# H6 register map
Vendor: Allwinner; Series: H6; File version: 0.1
CPU: CA53 0, little endian, MPU, no FPU, 0 interrupt priority bits
Registers are 32-bit, read-write, reset 0x0 unless marked. A register's access mark holds for its fields unless they carry their own. Offsets are from the block's base; [hi:lo] are bit positions; {n}, {i} and the like mark numbered series; 'fields as' and 'values as' point back to an identical list.

## CCU
Base 0x03001000
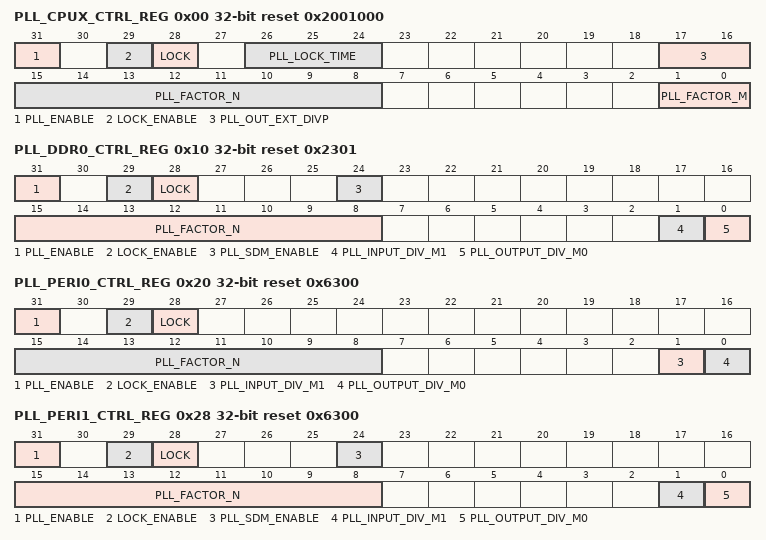
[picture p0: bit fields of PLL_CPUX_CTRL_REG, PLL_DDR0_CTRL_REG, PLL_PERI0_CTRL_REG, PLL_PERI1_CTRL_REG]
0x00 PLL_CPUX_CTRL_REG reset 0x2001000 — PLL_CPUX Control Register
  [31] PLL_ENABLE — 0: Disable. 1: Enable. The PLL_CPUX= 24MHz*N/P. NOTE The PLL_CPUX output clock must be in the range of 200MHz~3GHz. Its default value is 408MHz.
    0=Disable; 1=Enable. The PLL_CPUX= 24MHz*N/P. NOTE The PLL_CPUX output clock must be in the range of 200MHz~3GHz. Its default value is 408MHz.
  [29] LOCK_ENABLE — Lock Enable 0: Disable 1: Enable
    0=Disable; 1=Enable
  [28] LOCK ro — 0:Unlocked 1: Locked (It indicates that the PLL has been stable.)
    1=Locked (It indicates that the PLL has been stable.)
  [26:24] PLL_LOCK_TIME — PLL Lock Time. This bit is a stepping range from a frequency to another frequency,it can adjust the speed of clock changing.
  [17:16] PLL_OUT_EXT_DIVP — PLL Output External Divider P. 00: 1 01: 2 10: 4 11: / When output clock is less than 288MHz,clock frequency is outputted by dividing P.
    0=_1; 1=_2; 2=_4; 3=_slash_ (/ When output clock is less than 288MHz,clock frequency is outputted by dividing P.)
  [15:8] PLL_FACTOR_N — PLL Factor N. N= PLL_FACTOR_N +1 PLL_FACTOR_N is from 0 to 254. In application, PLL_FACTOR_N should be more than or equal to 11
  [1:0] PLL_FACTOR_M — PLL Factor M M = PLL_FACTOR_M + 1 PLL_FACTOR_M is from 0 to 3. M is only used for backdoor testing.
0x10 PLL_DDR0_CTRL_REG reset 0x2301 — PLL_DDR0 Control Register
  [31] PLL_ENABLE — 0: Disable. 1: Enable. The PLL_DDR0 = 24MHz*N/M0/M1. PLL_DDR0 is 432MHz by default.
    0=Disable; 1=Enable. The PLL_DDR0 = 24MHz*N/M0/M1. PLL_DDR0 is 432MHz by default.
  [29] LOCK_ENABLE — Lock Enable 0: Disable 1: Enable
    0=Disable; 1=Enable
  [28] LOCK ro — 0:Unlocked 1: Locked (It indicates that the PLL has been stable.)
    1=Locked (It indicates that the PLL has been stable.)
  [24] PLL_SDM_ENABLE — 0: Disable. 1: Enable.
    0=Disable; 1=Enable
  [15:8] PLL_FACTOR_N — PLL Factor N. N= PLL_FACTOR_N +1 PLL_FACTOR_N is from 0 to 254. In application, PLL_FACTOR_N should be more than or equal to 11.
  [1] PLL_INPUT_DIV_M1 — PLL Input Div M1. M1=PLL_INPUT_DIV_M1 + 1 PLL_INPUT_DIV_M1 is from 0 to 1.
  [0] PLL_OUTPUT_DIV_M0 — PLL Output Div M0. M0=PLL_OUTPUT_DIV_M0 + 1 PLL_OUTPUT_DIV_M0 is from 0 to 1.
0x20 PLL_PERI0_CTRL_REG reset 0x6300 — PLL_PERI0 Control Register
  [31] PLL_ENABLE — 0: Disable. 1: Enable. The PLL_PERI0(4X) = 24MHz*N/M0/M1. The PLL_PERI0(2X) = (24MHz*N/M0/M1)/2. The PLL_PERI0(1X) = (24MHz*N/M0/M1)/4. PLL_PERI0(4X) is 2.4GHz by default. PLL_PERI0(4X) output clock should be 2.4GHz. It is not suggested to change this parameter.
    0=Disable; 1=Enable. The PLL_PERI0(4X) = 24MHz*N/M0/M1. The PLL_PERI0(2X) = (24MHz*N/M0/M1)/2. The PLL_PERI0(1X) = (24MHz*N/M0/M1)/4. PLL_PERI0(4X) is 2.4GHz by default. PLL_PERI0(4X) output clock should be 2.4GHz. It is not suggested to change this parameter.
  [29] LOCK_ENABLE — Lock Enable 0: Disable 1: Enable
    0=Disable; 1=Enable
  [28] LOCK ro — 0:Unlocked 1: Locked (It indicates that the PLL has been stable.)
    1=Locked (It indicates that the PLL has been stable.)
  [15:8] PLL_FACTOR_N — PLL Factor N. N= PLL_FACTOR_N +1 PLL_FACTOR_N is from 0 to 254. In application, PLL_FACTOR_N should be more than or equal to 11
  [1] PLL_INPUT_DIV_M1 — PLL Input Div M1. M1=PLL_INPUT_DIV_M1 + 1 PLL_INPUT_DIV_M1 is from 0 to 1.
  [0] PLL_OUTPUT_DIV_M0 — PLL Output Div M0. M0=PLL_OUTPUT_DIV_M0 + 1 PLL_OUTPUT_DIV_M0 is from 0 to 1.
0x28 PLL_PERI1_CTRL_REG reset 0x6300 — PLL_PERI1 Control Register
  [31] PLL_ENABLE — 0: Disable. 1: Enable. The PLL_PERI1(4X) = 24MHz*N/M0/M1. The PLL_PERI1(2X) = (24MHz*N/M0/M1)/2. The PLL_PERI1(1X) = (24MHz*N/M0/M1)/4. PLL_PERI1(4X) is 2.4GHz by default. PLL_PERI1(4X) output clock should be 2.4GHz. It is not suggested to change this parameter.
    0=Disable; 1=Enable. The PLL_PERI1(4X) = 24MHz*N/M0/M1. The PLL_PERI1(2X) = (24MHz*N/M0/M1)/2. The PLL_PERI1(1X) = (24MHz*N/M0/M1)/4. PLL_PERI1(4X) is 2.4GHz by default. PLL_PERI1(4X) output clock should be 2.4GHz. It is not suggested to change this parameter.
  [29] LOCK_ENABLE — Lock Enable 0: Disable 1: Enable
    0=Disable; 1=Enable
  [28] LOCK ro — 0:Unlocked 1: Locked (It indicates that the PLL has been stable.)
    1=Locked (It indicates that the PLL has been stable.)
  [24] PLL_SDM_ENABLE — 0: Disable. 1: Enable.
    0=Disable; 1=Enable
  [15:8] PLL_FACTOR_N — PLL Factor N. N= PLL_FACTOR_N +1 PLL_FACTOR_N is from 0 to 254. In application, PLL_FACTOR_N should be more than or equal to 11.
  [1] PLL_INPUT_DIV_M1 — PLL Input Div M1. M1=PLL_INPUT_DIV_M1 + 1 PLL_INPUT_DIV_M1 is from 0 to 1.
  [0] PLL_OUTPUT_DIV_M0 — PLL Output Div M0. M0=PLL_OUTPUT_DIV_M0 + 1 PLL_OUTPUT_DIV_M0 is from 0 to 1.
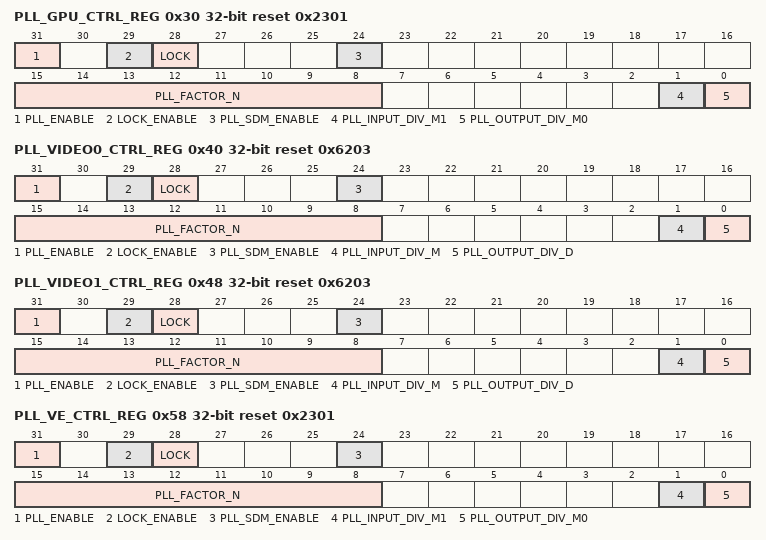
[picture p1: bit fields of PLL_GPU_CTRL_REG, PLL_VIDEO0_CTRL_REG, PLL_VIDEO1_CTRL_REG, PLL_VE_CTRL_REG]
0x30 PLL_GPU_CTRL_REG reset 0x2301 — PLL_GPU Control Register
  [31] PLL_ENABLE — 0: Disable. 1: Enable. The PLL_GPU = 24MHz*N/M0/M1. PLL_GPU is 432MHz by default.
    0=Disable; 1=Enable. The PLL_GPU = 24MHz*N/M0/M1. PLL_GPU is 432MHz by default.
  [29] LOCK_ENABLE — Lock Enable 0: Disable 1: Enable
    0=Disable; 1=Enable
  [28] LOCK ro — 0:Unlocked 1: Locked (It indicates that the PLL has been stable.)
    1=Locked (It indicates that the PLL has been stable.)
  [24] PLL_SDM_ENABLE — 0: Disable. 1: Enable.
    0=Disable; 1=Enable
  [15:8] PLL_FACTOR_N — PLL Factor N. N= PLL_FACTOR_N +1 PLL_FACTOR_N is from 0 to 254. In application, PLL_FACTOR_N should be more than or equal to 11.
  [1] PLL_INPUT_DIV_M1 — PLL Input Div M1. M1=PLL_INPUT_DIV_M1 + 1 PLL_INPUT_DIV_M1 is from 0 to 1.
  [0] PLL_OUTPUT_DIV_M0 — PLL Output Div M0. M0=PLL_OUTPUT_DIV_M0 + 1 PLL_OUTPUT_DIV_M0 is from 0 to 1.
0x40 PLL_VIDEO0_CTRL_REG reset 0x6203 — PLL_VIDEO0 Control Register
  [31] PLL_ENABLE — 0: Disable. 1: Enable. For application, PLL_VIDEO0(4X)= 24MHz*N/M. PLL_VIDEO0(1X)=24MHz*N/M/4. PLL_VIDEO0 is 1188MHz by default.
    0=Disable; 1=Enable. For application, PLL_VIDEO0(4X)= 24MHz*N/M. PLL_VIDEO0(1X)=24MHz*N/M/4. PLL_VIDEO0 is 1188MHz by default.
  [29] LOCK_ENABLE — Lock Enable 0: Disable 1: Enable
    0=Disable; 1=Enable
  [28] LOCK ro — 0:Unlocked 1: Locked (It indicates that the PLL has been stable.)
    1=Locked (It indicates that the PLL has been stable.)
  [24] PLL_SDM_ENABLE — 0: Disable. 1: Enable.
    0=Disable; 1=Enable
  [15:8] PLL_FACTOR_N — PLL Factor N. N= PLL_FACTOR_N +1 PLL_FACTOR_N is from 0 to 254. In application, PLL_FACTOR_N should be more than or equal to 11
  [1] PLL_INPUT_DIV_M — PLL Input Div M. M1=PLL_INPUT_DIV_M + 1 PLL_INPUT_DIV_M is from 0 to 1.
  [0] PLL_OUTPUT_DIV_D — PLL Output Div D. ( This factor is used for testing.) M0=PLL_OUTPUT_DIV_D + 1 PLL_OUTPUT_DIV_D is from 0 to 1. For test, PLL_VIDEO0(4X) =24MHz*N/M/D
0x48 PLL_VIDEO1_CTRL_REG reset 0x6203 — PLL_VIDEO1 Control Register
  [31] PLL_ENABLE — 0: Disable. 1: Enable. For application, PLL_VIDEO1(4X)= 24MHz*N/M. PLL_VIDEO1(1X)=24MHz*N/M/4. PLL_VIDEO0 is 1188MHz by default.
    0=Disable; 1=Enable. For application, PLL_VIDEO1(4X)= 24MHz*N/M. PLL_VIDEO1(1X)=24MHz*N/M/4. PLL_VIDEO0 is 1188MHz by default.
  [29] LOCK_ENABLE — Lock Enable 0: Disable 1: Enable
    0=Disable; 1=Enable
  [28] LOCK ro — 0:Unlocked 1: Locked (It indicates that the PLL has been stable.)
    1=Locked (It indicates that the PLL has been stable.)
  [24] PLL_SDM_ENABLE — 0: Disable. 1: Enable.
    0=Disable; 1=Enable
  [15:8] PLL_FACTOR_N — PLL Factor N. N= PLL_FACTOR_N +1 PLL_FACTOR_N is from 0 to 254. In application, PLL_FACTOR_N should be more than or equal to 11
  [1] PLL_INPUT_DIV_M — PLL Input Div M. M1=PLL_INPUT_DIV_M + 1 PLL_INPUT_DIV_M is from 0 to 1.
  [0] PLL_OUTPUT_DIV_D — PLL Output Div D.( This factor is used for testing.) M0=PLL_OUTPUT_DIV_D + 1 PLL_OUTPUT_DIV_M0 is from 0 to 1. For test, PLL_VIDEO1(4X) =24MHz*N/M/D
0x58 PLL_VE_CTRL_REG reset 0x2301 — PLL_VE Control Register
  [31] PLL_ENABLE — 0: Disable. 1: Enable. The PLL_VE = 24MHz*N/M0/M1. PLL_VE is 432MHz by default.
    0=Disable; 1=Enable. The PLL_VE = 24MHz*N/M0/M1. PLL_VE is 432MHz by default.
  [29] LOCK_ENABLE — Lock Enable 0: Disable 1: Enable
    0=Disable; 1=Enable
  [28] LOCK ro — 0:Unlocked 1: Locked (It indicates that the PLL has been stable.)
    1=Locked (It indicates that the PLL has been stable.)
  [24] PLL_SDM_ENABLE — 0: Disable. 1: Enable.
    0=Disable; 1=Enable
  [15:8] PLL_FACTOR_N — PLL Factor N. N= PLL_FACTOR_N +1 PLL_FACTOR_N is from 0 to 254. In application, PLL_FACTOR_N should be more than or equal to 11
  [1] PLL_INPUT_DIV_M1 — PLL Input Div M1. M1=PLL_INPUT_DIV_M1 + 1 PLL_INPUT_DIV_M1 is from 0 to 1.
  [0] PLL_OUTPUT_DIV_M0 — PLL Output Div M0. M0=PLL_OUTPUT_DIV_M0 + 1 PLL_OUTPUT_DIV_M0 is from 0 to 1.
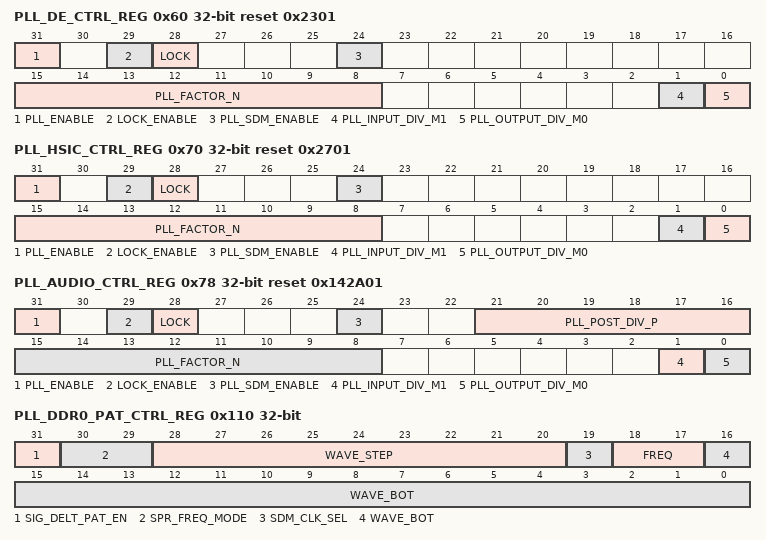
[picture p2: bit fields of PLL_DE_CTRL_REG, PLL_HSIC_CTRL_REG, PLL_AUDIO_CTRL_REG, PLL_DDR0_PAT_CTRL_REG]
0x60 PLL_DE_CTRL_REG reset 0x2301 — PLL_DE Control Register
  [31] PLL_ENABLE — 0: Disable. 1: Enable. The PLL_DE = 24MHz*N/M0/M1. PLL_DE is 432MHz by default.
    0=Disable; 1=Enable. The PLL_DE = 24MHz*N/M0/M1. PLL_DE is 432MHz by default.
  [29] LOCK_ENABLE — Lock Enable 0: Disable 1: Enable
    0=Disable; 1=Enable
  [28] LOCK ro — 0:Unlocked 1: Locked (It indicates that the PLL has been stable.)
    1=Locked (It indicates that the PLL has been stable.)
  [24] PLL_SDM_ENABLE — 0: Disable. 1: Enable.
    0=Disable; 1=Enable
  [15:8] PLL_FACTOR_N — PLL Factor N. N= PLL_FACTOR_N +1 PLL_FACTOR_N is from 0 to 254. In application, PLL_FACTOR_N should be more than or equal to 11
  [1] PLL_INPUT_DIV_M1 — PLL Input Div M1. M1=PLL_INPUT_DIV_M1 + 1 PLL_INPUT_DIV_M1 is from 0 to 1.
  [0] PLL_OUTPUT_DIV_M0 — PLL Output Div M0. M0=PLL_OUTPUT_DIV_M0 + 1 PLL_OUTPUT_DIV_M0 is from 0 to 1.
0x70 PLL_HSIC_CTRL_REG reset 0x2701 — PLL_HSIC Control Register
  [31] PLL_ENABLE — 0: Disable. 1: Enable. The PLL_HSIC = 24MHz*N/M0/M1. PLL_HSCI is 480MHz by default.
    0=Disable; 1=Enable. The PLL_HSIC = 24MHz*N/M0/M1. PLL_HSCI is 480MHz by default.
  [29] LOCK_ENABLE — Lock Enable 0: Disable 1: Enable
    0=Disable; 1=Enable
  [28] LOCK ro — 0:Unlocked 1: Locked (It indicates that the PLL has been stable.)
    1=Locked (It indicates that the PLL has been stable.)
  [24] PLL_SDM_ENABLE — 0: Disable. 1: Enable.
    0=Disable; 1=Enable
  [15:8] PLL_FACTOR_N — PLL Factor N. N= PLL_FACTOR_N +1 PLL_FACTOR_N is from 0 to 254. In application, PLL_FACTOR_N should be more than or equal to 11
  [1] PLL_INPUT_DIV_M1 — PLL Input Div M1. M1=PLL_INPUT_DIV_M1 + 1 PLL_INPUT_DIV_M1 is from 0 to 1.
  [0] PLL_OUTPUT_DIV_M0 — PLL Output Div M0. M0=PLL_OUTPUT_DIV_M0 + 1 PLL_OUTPUT_DIV_M0 is from 0 to 1.
0x78 PLL_AUDIO_CTRL_REG reset 0x142A01 — PLL_AUDIO Control Register
  [31] PLL_ENABLE — 0: Disable. 1: Enable. This PLL is for Audio. The PLL_AUDIO = 24MHz*N/(Input_div+1)/(Output_div+1)/(P+1). PLL_AUDIO(4X) = 24MHz*N/(Input_div+1)/2 PLL_AUDIO is 24.5714 MHz by default.
    0=Disable; 1=Enable. This PLL is for Audio. The PLL_AUDIO = 24MHz*N/(Input_div+1)/(Output_div+1)/(P+1). PLL_AUDIO(4X) = 24MHz*N/(Input_div+1)/2 PLL_AUDIO is 24.5714 MHz by default.
  [29] LOCK_ENABLE — Lock Enable 0: Disable 1: Enable
    0=Disable; 1=Enable
  [28] LOCK ro — 0:Unlocked 1: Locked (It indicates that the PLL has been stable.)
    1=Locked (It indicates that the PLL has been stable.)
  [24] PLL_SDM_ENABLE — 0: Disable. 1: Enable.
    0=Disable; 1=Enable
  [21:16] PLL_POST_DIV_P — PLL Post-div P. P= PLL_POST_DIV_P +1 PLL_POST_DIV_P is from 0 to 63.
  [15:8] PLL_FACTOR_N — PLL Factor N. N= PLL_FACTOR_N +1 PLL_FACTOR_N is from 0 to 254. In application, PLL_FACTOR_N should be more than or equal to 11
  [1] PLL_INPUT_DIV_M1 — PLL Input Div M1. M1=PLL_INPUT_DIV_M1 + 1 PLL_INPUT_DIV_M1 is from 0 to 1.
  [0] PLL_OUTPUT_DIV_M0 — PLL Output Div M0. M0=PLL_OUTPUT_DIV_M0 + 1 PLL_OUTPUT_DIV_M0 is from 0 to 1.
0x110 PLL_DDR0_PAT_CTRL_REG
  [31] SIG_DELT_PAT_EN — Sigma-Delta Pattern Enable.
  [30:29] SPR_FREQ_MODE — Spread Frequency Mode. 00: DC=0 01: DC=1 10: Triangular 11: Triangular
  [28:20] WAVE_STEP
  [19] SDM_CLK_SEL — SDM Clock Select 0: 24MHz 1: 12MHz When PLL_INPUT_DIV_M1 is 1,this register is set to 1.
    0=_24MHz; 1=12MHz When PLL_INPUT_DIV_M1 is 1,this register is set to 1
  [18:17] FREQ — Frequency. 00: 31.5kHz 01: 32kHz 10: 32.5kHz 11: 33kHz
    0=_31_point_5kHz (31.5kHz); 1=_32kHz; 2=_32_point_5kHz (32.5kHz); 3=_33kHz
  [16:0] WAVE_BOT — Wave Bottom.
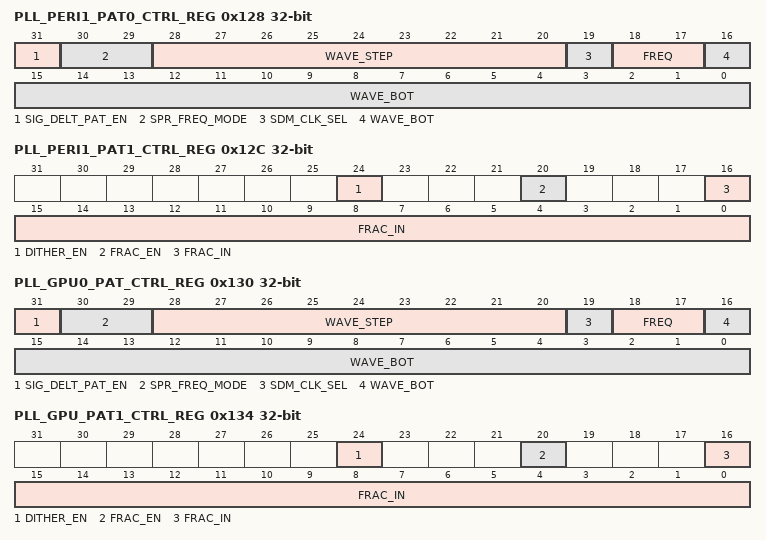
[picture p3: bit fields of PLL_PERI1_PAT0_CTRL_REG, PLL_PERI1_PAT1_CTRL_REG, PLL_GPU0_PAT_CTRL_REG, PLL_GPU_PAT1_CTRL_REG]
0x128 PLL_PERI1_PAT0_CTRL_REG
  fields as PLL_DDR0_PAT_CTRL_REG
0x12C PLL_PERI1_PAT1_CTRL_REG
  [24] DITHER_EN, [20] FRAC_EN, [16:0] FRAC_IN
0x130 PLL_GPU0_PAT_CTRL_REG
  fields as PLL_DDR0_PAT_CTRL_REG
0x134 PLL_GPU_PAT1_CTRL_REG
  [24] DITHER_EN, [20] FRAC_EN, [16:0] FRAC_IN
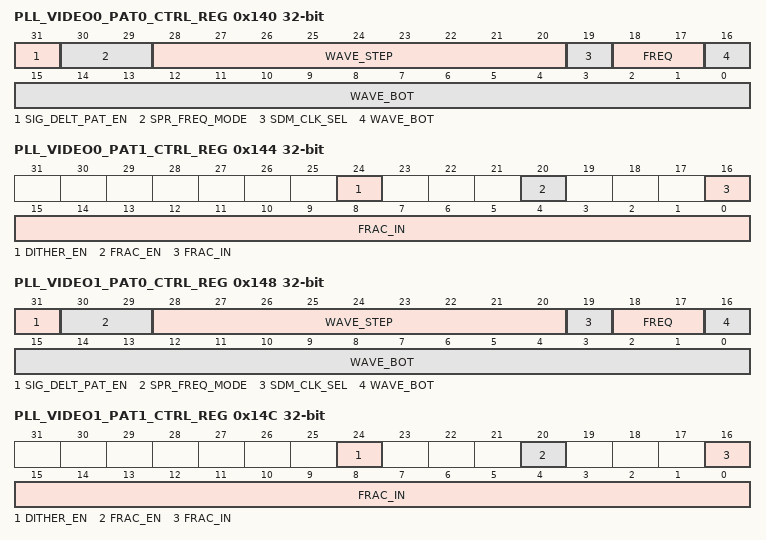
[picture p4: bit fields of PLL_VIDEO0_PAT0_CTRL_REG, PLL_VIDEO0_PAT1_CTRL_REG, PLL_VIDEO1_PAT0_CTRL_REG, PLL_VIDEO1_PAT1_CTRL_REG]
0x140 PLL_VIDEO0_PAT0_CTRL_REG
  [31] SIG_DELT_PAT_EN — Sigma-Delta Pattern Enable.
  [30:29] SPR_FREQ_MODE — Spread Frequency Mode. 00: DC=0 01: DC=1 10: Triangular 11: Triangular
  [28:20] WAVE_STEP
  [19] SDM_CLK_SEL — SDM Clock Select 0: 24MHz 1: 12MHz when PLL_INPUT_DIV_M1 is 1, this register is set to 1.
    0=_24MHz; 1=12MHz when PLL_INPUT_DIV_M1 is 1, this register is set to 1
  [18:17] FREQ — Frequency. 00: 31.5kHz 01: 32kHz 10: 32.5kHz 11: 33kHz
    values as PLL_DDR0_PAT_CTRL_REG.FREQ
  [16:0] WAVE_BOT — Wave Bottom.
0x144 PLL_VIDEO0_PAT1_CTRL_REG
  [24] DITHER_EN, [20] FRAC_EN, [16:0] FRAC_IN
0x148 PLL_VIDEO1_PAT0_CTRL_REG
  fields as PLL_VIDEO0_PAT0_CTRL_REG
0x14C PLL_VIDEO1_PAT1_CTRL_REG
  [24] DITHER_EN, [20] FRAC_EN, [16:0] FRAC_IN
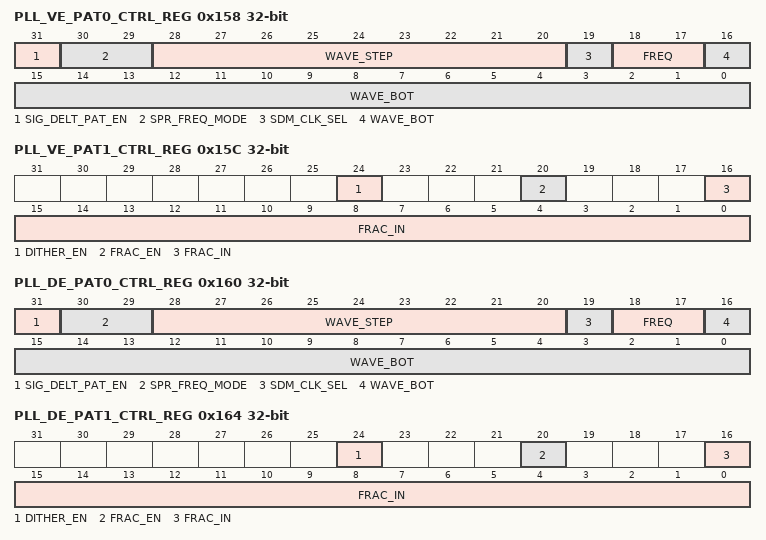
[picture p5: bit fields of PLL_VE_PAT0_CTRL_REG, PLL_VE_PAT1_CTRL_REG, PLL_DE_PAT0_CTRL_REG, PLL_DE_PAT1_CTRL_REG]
0x158 PLL_VE_PAT0_CTRL_REG
  [31] SIG_DELT_PAT_EN — Sigma-Delta Pattern Enable.
  [30:29] SPR_FREQ_MODE — Spread Frequency Mode. 00: DC=0 01: DC=1 10: Triangular(1bit) 11: Triangular(nbit)
    0=DC_equals_0 (DC=0); 1=DC_equals_1 (DC=1); 2=Triangular_openingparen_1bit_closingparen_ (Triangular(1bit)); 3=Triangular_openingparen_nbit_closingparen_ (Triangular(nbit))
  [28:20] WAVE_STEP
  [19] SDM_CLK_SEL — SDM Clock Select 0: 24MHz 1: 12MHz when PLL_INPUT_DIV_M1 is 1, this register is set to 1.
    values as PLL_VIDEO0_PAT0_CTRL_REG.SDM_CLK_SEL
  [18:17] FREQ — Frequency. 00: 31.5kHz 01: 32kHz 10: 32.5kHz 11: 33kHz
    values as PLL_DDR0_PAT_CTRL_REG.FREQ
  [16:0] WAVE_BOT — Wave Bottom.
0x15C PLL_VE_PAT1_CTRL_REG
  [24] DITHER_EN, [20] FRAC_EN, [16:0] FRAC_IN
0x160 PLL_DE_PAT0_CTRL_REG
  fields as PLL_VIDEO0_PAT0_CTRL_REG
0x164 PLL_DE_PAT1_CTRL_REG
  [24] DITHER_EN, [20] FRAC_EN, [16:0] FRAC_IN
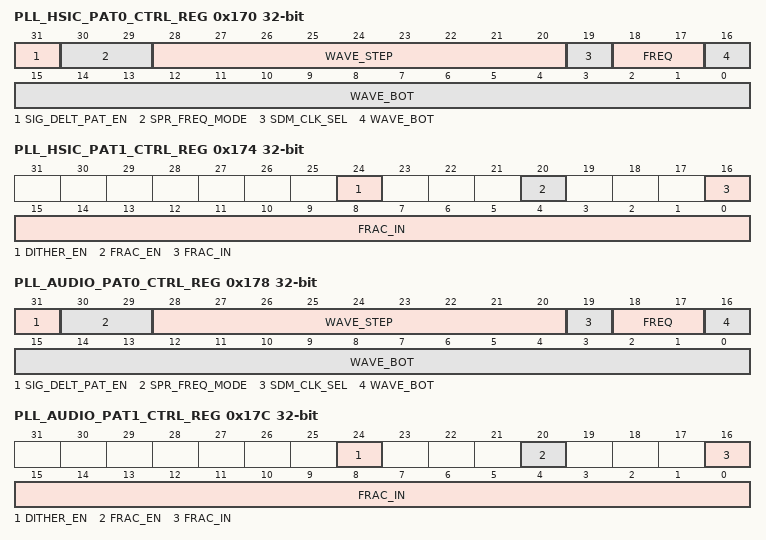
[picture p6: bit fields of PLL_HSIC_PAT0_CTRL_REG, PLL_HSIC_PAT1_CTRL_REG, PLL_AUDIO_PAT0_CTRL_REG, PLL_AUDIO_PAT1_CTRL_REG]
0x170 PLL_HSIC_PAT0_CTRL_REG
  fields as PLL_VIDEO0_PAT0_CTRL_REG
0x174 PLL_HSIC_PAT1_CTRL_REG
  [24] DITHER_EN, [20] FRAC_EN, [16:0] FRAC_IN
0x178 PLL_AUDIO_PAT0_CTRL_REG
  fields as PLL_VIDEO0_PAT0_CTRL_REG
0x17C PLL_AUDIO_PAT1_CTRL_REG
  [24] DITHER_EN, [20] FRAC_EN, [16:0] FRAC_IN
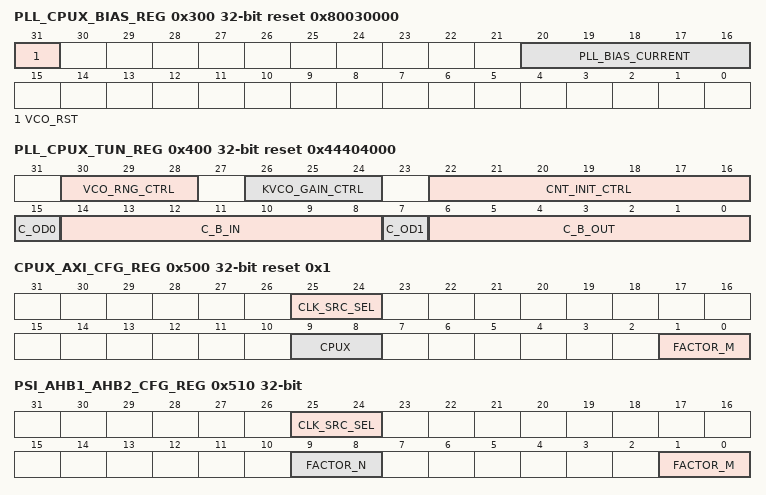
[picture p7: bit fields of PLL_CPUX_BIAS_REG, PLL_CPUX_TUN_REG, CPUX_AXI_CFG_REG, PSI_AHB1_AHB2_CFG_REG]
0x300 PLL_CPUX_BIAS_REG reset 0x80030000 — PLL_CPUX Bias Register
  [31] VCO_RST — VCO reset in.
  [20:16] PLL_BIAS_CURRENT — PLL current bias control [4:0], CPU_CP.
0x310 PLL_DDR0_BIAS_REG reset 0x30000 — PLL_DDR0 Bias Register
  [20:16] PLL_BIAS_CTRL — PLL bias control [4:0].
0x320 PLL_PERI0_BIAS_REG reset 0x30000 — PLL_PERI0 Bias Register
  [20:16] PLL_BIAS_CTRL — PLL bias control [4:0].
0x328 PLL_PERI1_BIAS_REG reset 0x30000 — PLL_PERI1 Bias Register
  [20:16] PLL_BIAS_CTRL — PLL bias control [4:0].
0x330 PLL_GPU_BIAS_REG reset 0x30000 — PLL_GPU Bias Register
  [20:16] PLL_BIAS_CTRL — PLL bias control [4:0].
0x340 PLL_VIDEO0_BIAS_REG reset 0x30000 — PLL_VIDEO0 Bias Register
  [20:16] PLL_BIAS_CTRL — PLL bias control [4:0].
0x348 PLL_VIDEO1_BIAS_REG reset 0x30000 — PLL_VIDEO1 Bias Register
  [20:16] PLL_BIAS_CTRL — PLL bias control [4:0].
0x358 PLL_VE_BIAS_REG reset 0x30000 — PLL_VE Bias Register
  [20:16] PLL_BIAS_CTRL — PLL bias control [4:0].
0x360 PLL_DE_BIAS_REG reset 0x30000 — PLL_DE Bias Register
  [20:16] PLL_BIAS_CTRL — PLL bias control [4:0].
0x370 PLL_HSIC_BIAS_REG reset 0x30000 — PLL_HSIC Bias Register
  [20:16] PLL_BIAS_CTRL — PLL bias control [4:0].
0x378 PLL_AUDIO_BIAS_REG reset 0x30000 — PLL_AUDIO Bias Register
  [20:16] PLL_BIAS_CTRL — PLL bias control [4:0].
0x400 PLL_CPUX_TUN_REG reset 0x44404000 — PLL_CPUX Tunning Register
  [30:28] VCO_RNG_CTRL — VCO range control [2:0].
  [26:24] KVCO_GAIN_CTRL — KVCO gain control [2:0].
  [22:16] CNT_INIT_CTRL — Counter initial control [6:0].
  [15] C_OD0 — C-REG-OD0 for verify.
  [14:8] C_B_IN — C-B-IN [6:0] for verify.
  [7] C_OD1 — C-REG-OD1 for verify.
  [6:0] C_B_OUT ro — C-B-OUT [6:0] for verify.
0x500 CPUX_AXI_CFG_REG reset 0x1 — CPUX_AXI Configuration Register
  [25:24] CLK_SRC_SEL — Clock Source Select 00: OSC24M 01: CCU_32K 10: RC16M 11: PLL_CPUX CPUX Clock = Clock Source CPUX_AXI Clock = Clock Source/M CPUX _APB Clock = Clock Source/N
    0=OSC24M; 1=CCU_32K; 2=RC16M; 3=PLL_CPUX (PLL_CPUX CPUX Clock = Clock Source CPUX_AXI Clock = Clock Source/M CPUX _APB Clock = Clock Source/N)
  [9:8] CPUX — _APB_FACTOR_N. Factor N.(N = FACTOR_N +1) The range is from 1 to 4
  [1:0] FACTOR_M — Factor M.(M= FACTOR_M +1) The range is from 1 to 4
0x510 PSI_AHB1_AHB2_CFG_REG — PSI_AHB1_AHB2 Configuration Register
  [25:24] CLK_SRC_SEL — Clock Source Select 00: OSC24M 01: CCU_32K 10: RC16M 11: PLL_PERI0(1X) PSI_AHB1_AHB2 CLK = Clock Source/M/N.
    0=OSC24M; 1=CCU_32K; 2=RC16M; 3=PLL_PERI0_openingparen_1X_closingparen_ (PLL_PERI0(1X) PSI_AHB1_AHB2 CLK = Clock Source/M/N.)
  [9:8] FACTOR_N — Factor N 00: 1 01: 2 10: 4 11: 8
    0=_1; 1=_2; 2=_4; 3=_8
  [1:0] FACTOR_M — Factor M.(M= FACTOR_M +1) The range is from 1 to 4
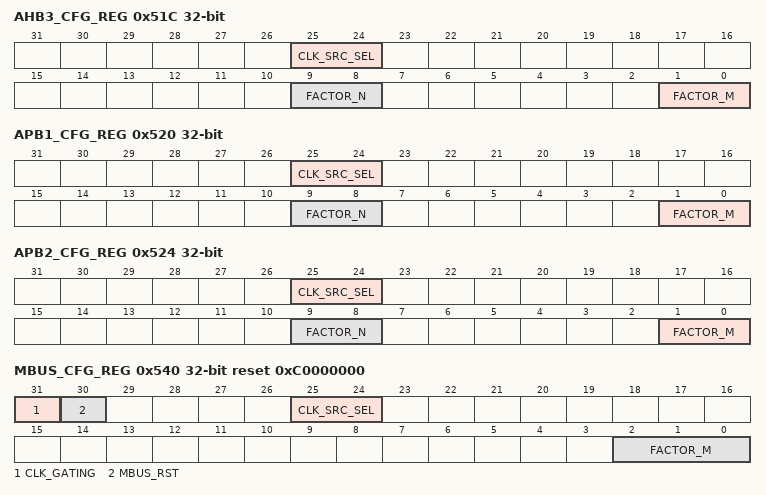
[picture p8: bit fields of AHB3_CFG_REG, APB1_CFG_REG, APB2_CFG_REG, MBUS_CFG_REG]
0x51C AHB3_CFG_REG — AHB3 Configuration Register
  [25:24] CLK_SRC_SEL — Clock Source Select 00: OSC24M 01: CCU_32K 10: PSI 11: PLL_PERI0(1X) AHB3 CLK = Clock Source/M/N.
    0=OSC24M; 1=CCU_32K; 2=PSI; 3=PLL_PERI0_openingparen_1X_closingparen_ (PLL_PERI0(1X) AHB3 CLK = Clock Source/M/N.)
  [9:8] FACTOR_N — Factor N 00: 1 01: 2 10: 4 11: 8
    0=_1; 1=_2; 2=_4; 3=_8
  [1:0] FACTOR_M — Factor M.(M= FACTOR_M +1) The range is from 1 to 4
0x520 APB1_CFG_REG — APB1 Configuration Register
  [25:24] CLK_SRC_SEL — Clock Source Select 00: OSC24M 01: CCU_32K 10: PSI 11: PLL_PERI0(1X) APB1 CLK = Clock Source/M/N.
    0=OSC24M; 1=CCU_32K; 2=PSI; 3=PLL_PERI0_openingparen_1X_closingparen_ (PLL_PERI0(1X) APB1 CLK = Clock Source/M/N.)
  [9:8] FACTOR_N — Factor N 00: 1 01: 2 10: 4 11: 8
    0=_1; 1=_2; 2=_4; 3=_8
  [1:0] FACTOR_M — Factor M.(M= FACTOR_M +1) The range is from 1 to 4
0x524 APB2_CFG_REG — APB2 Configuration Register
  [25:24] CLK_SRC_SEL — Clock Source Select 00: OSC24M 01: CCU_32K 10: PSI 11: PLL_PERI0(1X) APB2 CLK = Clock Source/M/N.
    0=OSC24M; 1=CCU_32K; 2=PSI; 3=PLL_PERI0_openingparen_1X_closingparen_ (PLL_PERI0(1X) APB2 CLK = Clock Source/M/N.)
  [9:8] FACTOR_N — Factor N 00: 1 01: 2 10: 4 11: 8
    0=_1; 1=_2; 2=_4; 3=_8
  [1:0] FACTOR_M — Factor M.(M= FACTOR_M +1) The range is from 1 to 4
0x540 MBUS_CFG_REG reset 0xC0000000 — MBUS Configuration Register
  [31] CLK_GATING — Gating Special Clock 0: Clock is OFF 1: Clock is ON MBUS CLK = Clock Source/M.
    0=OFF (Clock is OFF); 1=ON (Clock is ON MBUS CLK = Clock Source/M.)
  [30] MBUS_RST — MBUS Reset 0: Assert 1: De-assert
    0=Assert; 1=deassert
  [25:24] CLK_SRC_SEL — Clock Source Select 00: OSC24M 01: PLL_PERI0(2X) 10: PLL_DDR0 11: PLL_PERI0(4X)
    0=OSC24M; 1=PLL_PERI0_openingparen_2X_closingparen_ (PLL_PERI0(2X)); 2=PLL_DDR0; 3=PLL_PERI0_openingparen_4X_closingparen_ (PLL_PERI0(4X))
  [2:0] FACTOR_M — Factor M.(M= FACTOR_M +1) The range is from 1 to 8
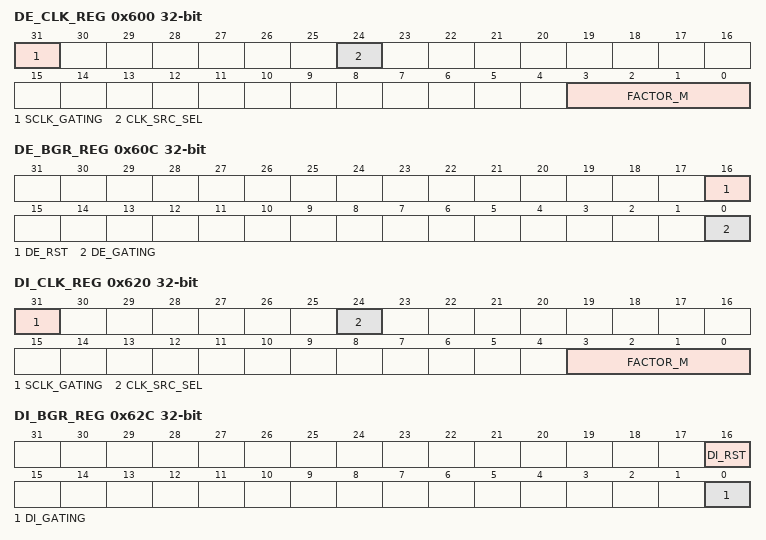
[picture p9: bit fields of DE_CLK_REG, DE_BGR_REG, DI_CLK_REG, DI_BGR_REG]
0x600 DE_CLK_REG — DE Clock Register
  [31] SCLK_GATING — Gating Special Clock 0: Clock is OFF 1: Clock is ON SCLK = Clock Source/M.
    0=OFF (Clock is OFF); 1=ON (Clock is ON SCLK = Clock Source/M.)
  [24] CLK_SRC_SEL — Clock Source Select 0: PLL_DE 1: PLL_PERI0(2X)
    0=PLL_DE; 1=PLL_PERI0_openingparen_2X_closingparen_ (PLL_PERI0(2X))
  [3:0] FACTOR_M — Factor M.(M= FACTOR_M +1) The range is from 1 to 16
0x60C DE_BGR_REG — DE Bus Gating Reset Register
  [16] DE_RST — DE Reset. 0: Assert 1: De-assert
    0=Assert; 1=deassert
  [0] DE_GATING — Gating Clock For DE 0: Mask 1: Pass
    0=Mask; 1=Pass
0x620 DI_CLK_REG — DI Clock Register
  [31] SCLK_GATING — Gating Special Clock 0: Clock is OFF 1: Clock is ON SCLK = Clock Source/M.
    values as DE_CLK_REG.SCLK_GATING
  [24] CLK_SRC_SEL — Clock Source Select 0: PLL_PERI0(1X) 1: PLL_PERI1(1X)
    0=PLL_PERI0_openingparen_1X_closingparen_ (PLL_PERI0(1X)); 1=PLL_PERI1_openingparen_1X_closingparen_ (PLL_PERI1(1X))
  [3:0] FACTOR_M — Factor M.(M= FACTOR_M +1) The range is from 1 to 16
0x62C DI_BGR_REG — DI Bus Gating Reset Register
  [16] DI_RST — DI Reset. 0: Assert 1: De-assert
    0=Assert; 1=deassert
  [0] DI_GATING — Gating Clock For DI 0: Mask 1: Pass
    0=Mask; 1=Pass
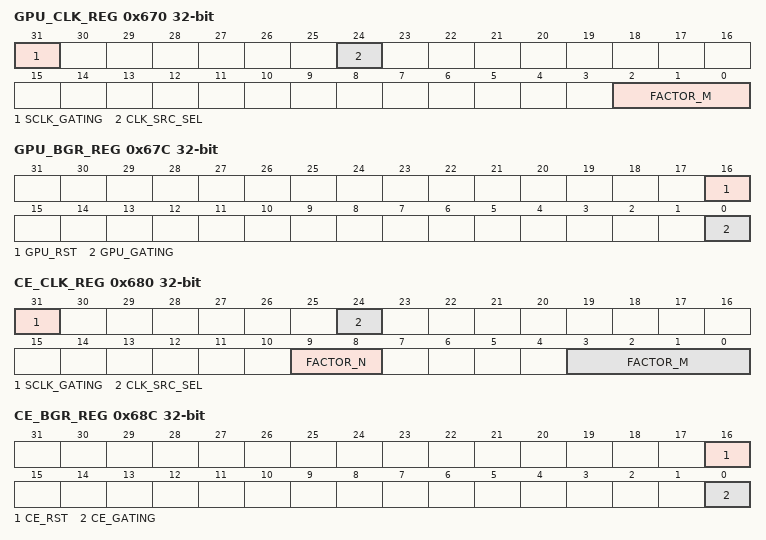
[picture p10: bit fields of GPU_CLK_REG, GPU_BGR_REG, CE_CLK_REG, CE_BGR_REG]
0x670 GPU_CLK_REG — GPU Clock Register
  [31] SCLK_GATING — Gating Special Clock 0: Clock is OFF 1: Clock is ON SCLK = Clock Source/M.
    values as DE_CLK_REG.SCLK_GATING
  [24] CLK_SRC_SEL — Clock Source Select 0: PLL_GPU 1: /
    0=PLL_GPU
  [2:0] FACTOR_M — Factor M.(M= FACTOR_M +1) The range is from 1 to 8
0x67C GPU_BGR_REG — GPU Bus Gating Reset Register
  [16] GPU_RST — GPU Reset. 0: Assert 1: De-assert
    0=Assert; 1=deassert
  [0] GPU_GATING — Gating Clock For GPU 0: Mask 1: Pass
    0=Mask; 1=Pass
0x680 CE_CLK_REG — CE Clock Register
  [31] SCLK_GATING — Gating Special Clock 0: Clock is OFF 1: Clock is ON SCLK = Clock Source/M/N.
    0=OFF (Clock is OFF); 1=ON (Clock is ON SCLK = Clock Source/M/N.)
  [24] CLK_SRC_SEL — Clock Source Select 0: OSC24M 1: PLL_PERI0(2X)
    0=OSC24M; 1=PLL_PERI0_openingparen_2X_closingparen_ (PLL_PERI0(2X))
  [9:8] FACTOR_N — Factor N 00: 1 01: 2 10: 4 11: 8
    0=_1; 1=_2; 2=_4; 3=_8
  [3:0] FACTOR_M — Factor M.(M= FACTOR_M +1) The range is from 1 to 16
0x68C CE_BGR_REG — CE Bus Gating Reset Register
  [16] CE_RST — CE Reset. 0: Assert 1: De-assert
    0=Assert; 1=deassert
  [0] CE_GATING — Gating Clock For CE 0: Mask 1: Pass
    0=Mask; 1=Pass
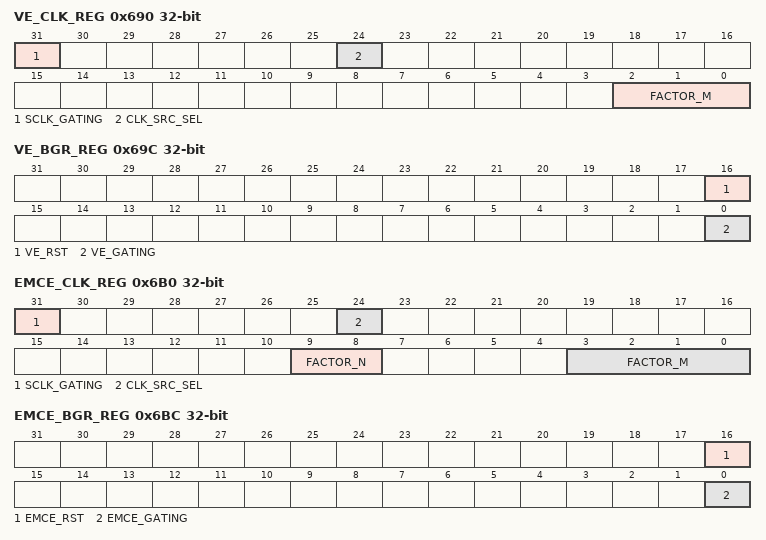
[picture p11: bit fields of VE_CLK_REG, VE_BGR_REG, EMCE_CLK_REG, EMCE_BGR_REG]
0x690 VE_CLK_REG — VE Clock Register
  [31] SCLK_GATING — Gating Special Clock 0: Clock is OFF 1: Clock is ON SCLK = Clock Source/Divider M.
    0=OFF (Clock is OFF); 1=ON (Clock is ON SCLK = Clock Source/Divider M.)
  [24] CLK_SRC_SEL — Clock Source Select 0: PLL_VE 1: /
    0=PLL_VE
  [2:0] FACTOR_M — Factor M.(M= FACTOR_M +1) The range is from 1 to 8
0x69C VE_BGR_REG — VE Bus Gating Reset Register
  [16] VE_RST — VE Reset. 0: Assert 1: De-assert
    0=Assert; 1=deassert
  [0] VE_GATING — Gating Clock For VE 0: Mask 1: Pass
    0=Mask; 1=Pass
0x6B0 EMCE_CLK_REG — EMCE Clock Register
  [31] SCLK_GATING — Gating Special Clock 0: Clock is OFF 1: Clock is ON SCLK = Clock Source/M/N.
    values as CE_CLK_REG.SCLK_GATING
  [24] CLK_SRC_SEL — Clock Source Select 0: OSC24M 1: PLL_PERI0(2X)
    values as CE_CLK_REG.CLK_SRC_SEL
  [9:8] FACTOR_N — Factor N 00: /1 01: /2 10: /4 11: /8
    0=_slash_1 (/1); 1=_slash_2 (/2); 2=_slash_4 (/4); 3=_slash_8 (/8)
  [3:0] FACTOR_M — Factor M.(M= FACTOR_M +1) FACTOR_M is from 0 to 15
0x6BC EMCE_BGR_REG
  [16] EMCE_RST — EMCE Reset. 0: Assert 1: De-assert
    0=Assert; 1=deassert
  [0] EMCE_GATING — Gating Clock For EMCE 0: Mask 1: Pass
    0=Mask; 1=Pass
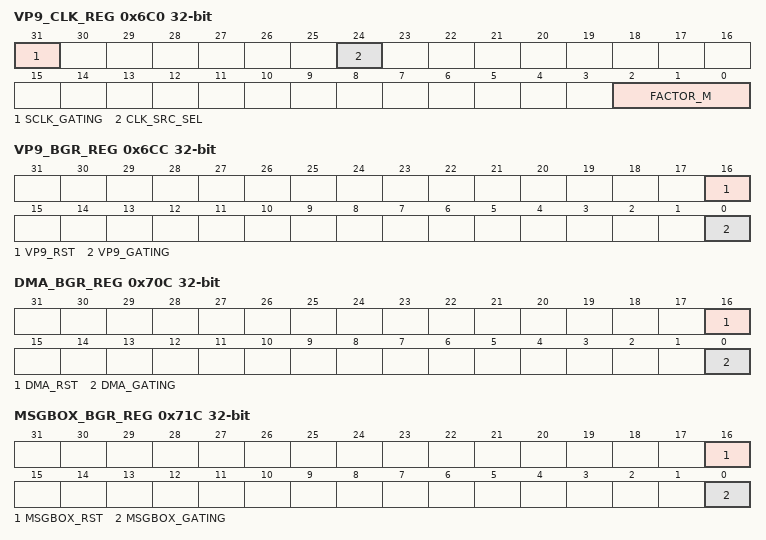
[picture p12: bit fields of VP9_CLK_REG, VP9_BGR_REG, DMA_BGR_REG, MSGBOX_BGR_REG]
0x6C0 VP9_CLK_REG — VP9 Clock Register
  [31] SCLK_GATING — Gating Special Clock 0: Clock is OFF 1: Clock is ON SCLK = Clock Source/Divider M.
    values as VE_CLK_REG.SCLK_GATING
  [24] CLK_SRC_SEL — Clock Source Select 0: PLL_VE 1: PLL_PERI0(2X)
    0=PLL_VE; 1=PLL_PERI0_openingparen_2X_closingparen_ (PLL_PERI0(2X))
  [2:0] FACTOR_M — Factor M.(M= FACTOR_M +1) FACTOR_M is from 0 to 7.
0x6CC VP9_BGR_REG
  [16] VP9_RST — VP9 Reset. 0: Assert 1: De-assert
    0=Assert; 1=deassert
  [0] VP9_GATING — Gating Clock For VP9 0: Mask 1: Pass
    0=Mask; 1=Pass
0x70C DMA_BGR_REG — DMA Bus Gating Reset Register
  [16] DMA_RST — DMA Reset. 0: Assert 1: De-assert
    0=Assert; 1=deassert
  [0] DMA_GATING — Gating Clock For DMA 0: Mask 1: Pass
    0=Mask; 1=Pass
0x71C MSGBOX_BGR_REG — MessageBox Bus Gating Reset Register
  [16] MSGBOX_RST — MSGBOX Reset. 0: Assert 1: De-assert
    0=Assert; 1=deassert
  [0] MSGBOX_GATING — Gating Clock For MSGBOX 0: Mask 1: Pass
    0=Mask; 1=Pass
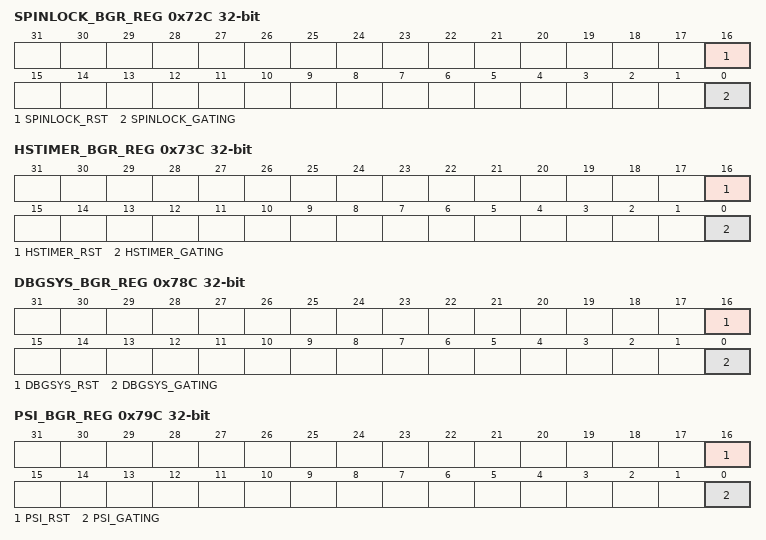
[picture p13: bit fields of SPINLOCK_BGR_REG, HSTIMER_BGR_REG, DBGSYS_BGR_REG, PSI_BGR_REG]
0x72C SPINLOCK_BGR_REG — Spinlock Bus Gating Reset Register
  [16] SPINLOCK_RST — SPINLOCK Reset. 0: Assert 1: De-assert
    0=Assert; 1=deassert
  [0] SPINLOCK_GATING — Gating Clock For SPINLOCK 0: Mask 1: Pass
    0=Mask; 1=Pass
0x73C HSTIMER_BGR_REG — HSTimer Bus Gating Reset Register
  [16] HSTIMER_RST — HSTIMER Reset. 0: Assert 1: De-assert
    0=Assert; 1=deassert
  [0] HSTIMER_GATING — Gating Clock For HSTIMER 0: Mask 1: Pass
    0=Mask; 1=Pass
0x740 AVS_CLK_REG — AVS Clock Register
  [31] SCLK_GATING — Gating Special Clock 0: Clock is OFF 1: Clock is ON SCLK = OSC24M.
    0=OFF (Clock is OFF); 1=ON (Clock is ON SCLK = OSC24M.)
0x78C DBGSYS_BGR_REG — DBGSYS Bus Gating Reset Register
  [16] DBGSYS_RST — DBGSYS Reset. 0: Assert 1: De-assert
    0=Assert; 1=deassert
  [0] DBGSYS_GATING — Gating Clock For DBGSYS 0: Mask 1: Pass
    0=Mask; 1=Pass
0x79C PSI_BGR_REG — PSI Bus Gating Reset Register
  [16] PSI_RST — PSI Reset. 0: Assert 1: De-assert
    0=Assert; 1=deassert
  [0] PSI_GATING — Gating Clock For PSI 0: Mask 1: Pass
    0=Mask; 1=Pass
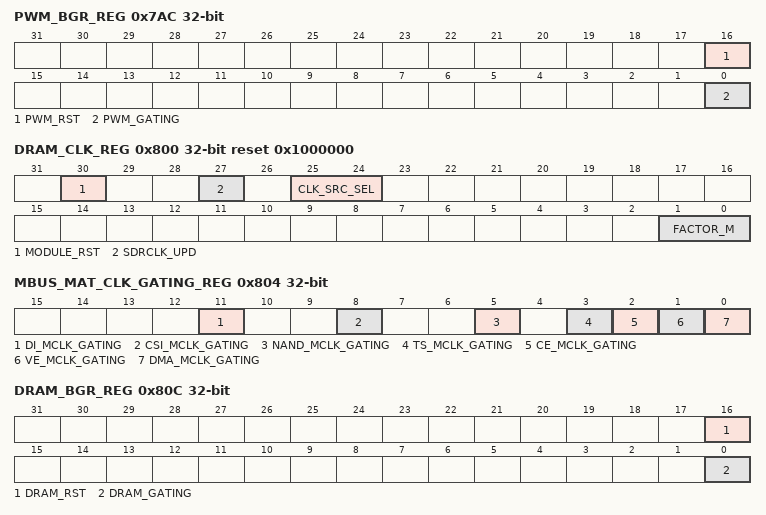
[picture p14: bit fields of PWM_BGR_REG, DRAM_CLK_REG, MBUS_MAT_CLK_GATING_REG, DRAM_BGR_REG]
0x7AC PWM_BGR_REG — PWM Bus Gating Reset Register
  [16] PWM_RST — PWM Reset. 0: Assert 1: De-assert
    0=Assert; 1=deassert
  [0] PWM_GATING — Gating Clock For PWM 0: Mask 1: Pass
    0=Mask; 1=Pass
0x7BC IOMMU_BGR_REG — IOMMU Bus Gating Reset Register
  [0] IOMMU_GATING — Gating Clock For IOMMU 0: Mask 1: Pass
    0=Mask; 1=Pass
0x800 DRAM_CLK_REG reset 0x1000000 — DRAM Clock Register
  [30] MODULE_RST — Module Reset 0: Assert 1: De-assert SCLK = Clock Source/M.
    0=Assert; 1=De-assert SCLK = Clock Source/M
  [27] SDRCLK_UPD — SDRCLK Configuration 0 update. 0:Invalid 1:Valid Setting this bit will validate Configuration 0. It will be auto cleared after the Configuration 0 is valid.
  [25:24] CLK_SRC_SEL — Clock Source Select 00: PLL_DDR0 Others: /
    0=PLL_DDR0 (PLL_DDR0 Others: /)
  [1:0] FACTOR_M — Factor M.(M= FACTOR_M +1) The range is from 1 to 4
0x804 MBUS_MAT_CLK_GATING_REG
  [all] fields
    0=Mask; 1=Pass
  [11] DI_MCLK_GATING — Gating MBUS Clock For DE_Interlace 0: Mask 1: Pass
  [8] CSI_MCLK_GATING — Gating MBUS Clock For CSI 0: Mask 1: Pass
  [5] NAND_MCLK_GATING — Gating MBUS Clock For NAND 0: Mask 1: Pass
  [3] TS_MCLK_GATING — Gating MBUS Clock For TS 0: Mask 1: Pass
  [2] CE_MCLK_GATING — Gating MBUS Clock For CE 0: Mask 1: Pass
  [1] VE_MCLK_GATING — Gating MBUS Clock For VE 0: Mask 1: Pass
  [0] DMA_MCLK_GATING — Gating MBUS Clock For DMA 0: Mask 1: Pass
0x80C DRAM_BGR_REG — DRAM Bus Gating Reset Register
  [16] DRAM_RST — DRAM Reset. 0: Assert 1: De-assert
    0=Assert; 1=deassert
  [0] DRAM_GATING — Gating Clock For DRAM 0: Mask 1: Pass
    0=Mask; 1=Pass
0x810 NAND_0_CLK_REG — NAND0 Clock Register
  [31] SCLK_GATING — Gating Special Clock 0: Clock is OFF 1: Clock is ON SCLK = Clock Source/M/N.
    values as CE_CLK_REG.SCLK_GATING
  [26:24] CLK_SRC_SEL — Clock Source Select 000: OSC24M 001: PLL_PERI0(1X) 010: PLL_PERI1(1X) 011: PLL_PERI0(2X) 100: PLL_PERI1(2X) 1XX:/
    0=OSC24M; 1=PLL_PERI0_openingparen_1X_closingparen_ (PLL_PERI0(1X)); 2=PLL_PERI1_openingparen_1X_closingparen_ (PLL_PERI1(1X)); 3=PLL_PERI0_openingparen_2X_closingparen_ (PLL_PERI0(2X)); 4=PLL_PERI1_openingparen_2X_closingparen_ (PLL_PERI1(2X) 1XX:/)
  [9:8] FACTOR_N — Factor N 00: 1 01: 2 10: 4 11: 8
    0=_1; 1=_2; 2=_4; 3=_8
  [3:0] FACTOR_M — Factor M.(M= FACTOR_M +1) FACTOR_M is from 0 to 15
0x814 NAND_1_CLK_REG — NAND1 Clock Register
  fields as NAND_0_CLK_REG
0x82C NAND_BGR_REG — NAND Bus Gating Reset Register
  [16] NAND_RST — NAND Reset. 0: Assert 1: De-assert
    0=Assert; 1=deassert
  [0] NAND_GATING — Gating Clock For NAND 0: Mask 1: Pass
    0=Mask; 1=Pass
0x830 SMHC0_CLK_REG — SMHC0 Clock Register
  [31] SCLK_GATING — Gating Special Clock 0: Clock is OFF 1: Clock is ON SCLK = Clock Source/M/N.
    values as CE_CLK_REG.SCLK_GATING
  [25:24] CLK_SRC_SEL — Clock Source Select 000: OSC24M 001: PLL_PERI0(2X) 010: PLL_PERI1(2X) 011: /
  [9:8] FACTOR_N — Factor N 00: 1 01: 2 10: 4 11: 8
    0=_1; 1=_2; 2=_4; 3=_8
  [3:0] FACTOR_M — Factor M.(M= FACTOR_M +1) FACTOR_M is from 0 to 15
0x834 SMHC1_CLK_REG — SMHC1 Clock Register
  [31] SCLK_GATING — Gating Special Clock 0: Clock is OFF 1: Clock is ON SCLK = Clock Source/M/N.
    values as CE_CLK_REG.SCLK_GATING
  [25:24] CLK_SRC_SEL — Clock Source Select 000: OSC24M 001: PLL_PERI0(2X) 010: PLL_PERI1(2X) 011: /
  [9:8] FACTOR_N — Factor N 00: 1 01: 2 10: 4 11: 8
    0=_1; 1=_2; 2=_4; 3=_8
  [3:0] FACTOR_M — Factor M.(M= FACTOR_M +1) The range is from 1 to 16
0x838 SMHC2_CLK_REG — SMHC2 Clock Register
  fields as SMHC0_CLK_REG
0x84C SMHC_BGR_REG — SMHC Bus Gating Reset Register
  [18] SMHC2_RST — SMHC2 Reset. 0: Assert 1: De-assert
    0=Assert; 1=deassert
  [17] SMHC1_RST — SMHC1 Reset. 0: Assert 1: De-assert
    0=Assert; 1=deassert
  [16] SMHC0_RST — SMHC0 Reset. 0: Assert 1: De-assert
    0=Assert; 1=deassert
  [2] SMHC2_GATING — Gating Clock For SMHC2 0: Mask 1: Pass
    0=Mask; 1=Pass
  [1] SMHC1_GATING — Gating Clock For SMHC1 0: Mask 1: Pass
    0=Mask; 1=Pass
  [0] SMHC0_GATING — Gating Clock For SMHC0 0: Mask 1: Pass
    0=Mask; 1=Pass
0x90C UART_BGR_REG — UART Bus Gating Reset Register
  [n+16] UART{n}_RST (n=0..3) — UART{n} Reset. 0: Assert 1: De-assert
    0=Assert; 1=deassert
  [n] UART{n}_GATING (n=0..3) — Gating Clock For UART{n} 0: Mask 1: Pass
    0=Mask; 1=Pass
0x91C TWI_BGR_REG — TWI Bus Gating Reset Register
  [n+16] TWI{n}_RST (n=0..3) — TWI{n} Reset. 0: Assert 1: De-assert
    0=Assert; 1=deassert
  [n] TWI{n}_GATING (n=0..3) — Gating Clock For TWI{n} 0: Mask 1: Pass
    0=Mask; 1=Pass
0x93C SCR_BGR_REG — SCR Bus Gating Reset Register
  [17] SCR1_RST — SCR1 Reset. 0: Assert 1: De-assert
    0=Assert; 1=deassert
  [16] SCR0_RST — SCR0 Reset. 0: Assert 1: De-assert
    0=Assert; 1=deassert
  [1] SCR1_GATING — Gating Clock For SCR1 0: Mask 1: Pass
    0=Mask; 1=Pass
  [0] SCR0_GATING — Gating Clock For SCR0 0: Mask 1: Pass
    0=Mask; 1=Pass
0x940 SPI0_CLK_REG — SPI0 Clock Register
  fields as NAND_0_CLK_REG
0x944 SPI1_CLK_REG — SPI1 Clock Register
  fields as NAND_0_CLK_REG
0x96C SPI_BGR_REG — SPI Bus Gating Reset Register
  [17] SPI1_RST — SPI1 Reset. 0: Assert 1: De-assert
    0=Assert; 1=deassert
  [16] SPI0_RST — SPI0 Reset. 0: Assert 1: De-assert
    0=Assert; 1=deassert
  [1] SPI1_GATING — Gating Clock For SPI1 0: Mask 1: Pass
    0=Mask; 1=Pass
  [0] SPI0_GATING — Gating Clock For SPI0 0: Mask 1: Pass
    0=Mask; 1=Pass
0x97C EMAC_BGR_REG — EMAC Bus Gating Reset Register
  [16] EMAC_RST — EMAC Reset. 0: Assert 1: De-assert
    0=Assert; 1=deassert
  [0] EMAC_GATING — Gating Clock For EMAC 0: Mask 1: Pass
    0=Mask; 1=Pass
0x9B0 TS_CLK_REG — TS Clock Register
  [31] SCLK_GATING — Gating Special Clock 0: Clock is OFF 1: Clock is ON SCLK = Clock Source/M/N.
    values as CE_CLK_REG.SCLK_GATING
  [24] CLK_SRC_SEL — Clock Source Select 0: OSC24M 1: PLL_PERI0(1X)
    0=OSC24M; 1=PLL_PERI0_openingparen_1X_closingparen_ (PLL_PERI0(1X))
  [9:8] FACTOR_N — Factor N 00: 1 01: 2 10: 4 11: 8
    0=_1; 1=_2; 2=_4; 3=_8
  [3:0] FACTOR_M — Factor M.(M= FACTOR_M +1) FACTOR_M is from 0 to 15
0x9BC TS_BGR_REG — TS Bus Gating Reset Register
  [16] TS0_RST — TS0 Reset. 0: Assert 1: De-assert
    0=Assert; 1=deassert
  [0] TS0_GATING — Gating Clock For TS0 0: Mask 1: Pass
    0=Mask; 1=Pass
0x9C0 CIRTX_CLK_REG
  [31] SCLK_GATING — Gating Special Clock 0: Clock is OFF 1: Clock is ON SCLK = Clock Source/M/N.
    values as CE_CLK_REG.SCLK_GATING
  [24] CLK_SRC_SEL — Clock Source Select 0: CCU_32K 1: OSC24M
    0=CCU_32K; 1=OSC24M
  [9:8] FACTOR_N — Factor N 00: 1 01: 2 10: 4 11: 8
    0=_1; 1=_2; 2=_4; 3=_8
  [3:0] FACTOR_M — Factor M.(M= FACTOR_M +1) FACTOR_M is from 0 to 15
0x9CC CIRTX_BGR_REG
  [16] CIRTX_RST — CIRTX Reset. 0: Assert 1: De-assert
    0=Assert; 1=deassert
  [0] CIRTX_GATING — Gating Clock For CIRTX 0: Mask 1: Pass
    0=Mask; 1=Pass
0x9FC THS_BGR_REG — THS Bus Gating Reset Register
  [16] THS_RST — THS Reset. 0: Assert 1: De-assert
    0=Assert; 1=deassert
  [0] THS_GATING — Gating Clock For THS 0: Mask 1: Pass
    0=Mask; 1=Pass
0xA0C I2S_PCM3_CLK_REG
  [31] SCLK_GATING — Gating Special Clock 0: Clock is OFF 1: Clock is ON SCLK = Clock Source/N.
    0=OFF (Clock is OFF); 1=ON (Clock is ON SCLK = Clock Source/N.)
  [25:24] CLK_SRC_SEL — Clock Source Select 00: PLL_AUDIO 01: PLL_AUDIO(2X) 10: PLL_AUDIO(4X) 11: /
    0=PLL_AUDIO; 1=PLL_AUDIO_openingparen_2X_closingparen_ (PLL_AUDIO(2X)); 2=PLL_AUDIO_openingparen_4X_closingparen_ (PLL_AUDIO(4X))
  [9:8] FACTOR_N — Factor N 00: 1 01: 2 10: 4 11: 8
    0=_1; 1=_2; 2=_4; 3=_8
{0xA10+4i} I2S_PCM{i}_CLK_REG (i=0..2)
  fields as I2S_PCM3_CLK_REG
0xA1C I2S_PCM_BGR_REG
  [n+16] I2S/PCM{n}_RST (n=0..3) — I2S/PCM{n} Reset. 0: Assert 1: De-assert
    0=Assert; 1=deassert
  [n] I2S/PCM{n}_GATING (n=0..3) — Gating Clock For I2S/PCM{n} 0: Mask 1: Pass
    0=Mask; 1=Pass
0xA20 OWA_CLK_REG — OWA Clock Register
  fields as I2S_PCM3_CLK_REG
0xA2C OWA_BGR_REG — OWA Bus Gating Reset Register
  [16] OWA_RST — OWA Reset. 0: Assert 1: De-assert
    0=Assert; 1=deassert
  [0] OWA_GATING — Gating Clock For OWA 0: Mask 1: Pass
    0=Mask; 1=Pass
0xA40 DMIC_CLK_REG — DMIC Clock Register
  fields as I2S_PCM3_CLK_REG
0xA4C DMIC_BGR_REG — DMIC Bus Gating Reset Register
  [16] DMIC_RST — DMIC Reset. 0: Assert 1: De-assert
    0=Assert; 1=deassert
  [0] DMIC_GATING — Gating Clock For DMIC 0: Mask 1: Pass
    0=Mask; 1=Pass
0xA60 AUDIO_HUB_CLK_REG
  fields as I2S_PCM3_CLK_REG
0xA6C AUDIO_HUB_BGR_REG — AUDIO_HUB Bus Gating Reset Register
  [16] AUDIO_HUB_RST — AUDIO_HUB Reset. 0: Assert 1: De-assert
    0=Assert; 1=deassert
  [0] AUDIO_HUB_GATING — Gating Clock For AUDIO_HUB 0: Mask 1: Pass
    0=Mask; 1=Pass
0xA70 USB0_CLK_REG — USB0 Clock Register
  [31] SCLK_GATING_OHCI0 — Gating Special Clock For OHCI0 0: Clock is OFF 1: Clock is ON
    0=OFF (Clock is OFF); 1=ON (Clock is ON)
  [30] USBPHY0_RST — USB PHY0 Reset 0: Assert 1: De-assert
    0=Assert; 1=deassert
  [29] SCLK_GATING_USBPHY0 — Gating Special Clock For USBPHY0 0: Clock is OFF 1: Clock is ON SCLK is from OSC24M
    0=OFF (Clock is OFF); 1=ON (Clock is ON SCLK is from OSC24M)
  [25:24] OHCI0_12M_SRC_SEL — OHCI0 12M Source Select 00: 12MHz divided from 48MHz 01: 12MHz divided from 24MHz 10: LOSC 11: /
0xA74 USB1_CLK_REG — USB1 Clock Register
  [30] USBPHY1_RST — USB PHY1 Reset 0: Assert 1: De-assert
    0=Assert; 1=deassert
  [29] SCLK_GATING_USBPHY1 — Gating Special Clock For USBPHY1 0: Clock is OFF 1: Clock is ON
    0=OFF (Clock is OFF); 1=ON (Clock is ON)
0xA7C USB3_CLK_REG — USB3 Clock Register
  [31] SCLK_GATING_OHCI3 — Gating Special Clock For OHCI3 0: Clock is OFF 1: Clock is ON
    0=OFF (Clock is OFF); 1=ON (Clock is ON)
  [30] USBPHY3_RST — USB PHY3 Reset 0: Assert 1: De-assert
    0=Assert; 1=deassert
  [29] SCLK_GATING_USBPHY3 — Gating Special Clock For USBPHY3 0: Clock is OFF 1: Clock is ON SCLK is from OSC24M
    0=OFF (Clock is OFF); 1=ON (Clock is ON SCLK is from OSC24M)
  [28] USBHSIC_RST — USB HSIC Reset 0: Assert 1: De-assert
    0=Assert; 1=deassert
  [27] SCLK_GATING_12M_HSIC — Gating Special 12M Clock For HSIC 0: Clock is OFF 1: Clock is ON SCLK is OSC24M/2
    0=OFF (Clock is OFF); 1=ON (Clock is ON SCLK is OSC24M/2)
  [26] SCK_GATING_HSIC — Gating Special Clock For HSIC 0: Clock is OFF 1: Clock is ON The special clock is from PLL_HSIC
    0=OFF (Clock is OFF); 1=ON (Clock is ON The special clock is from PLL_HSIC)
  [25:24] OHCI3_12M_SRC_SEL — OHCI3 12M Source Select 00: 12M divided from 48MHz 01: 12M divided from 24MHz 10: LOSC 11: /
0xA8C USB_BGR_REG
  [24] USBOTG_RST — USBOTG Reset. 0: Assert 1: De-assert
    0=Assert; 1=deassert
  [23] USBEHCI3_RST — USBEHCI3 Reset. 0: Assert 1: De-assert
    0=Assert; 1=deassert
  [21] USB3_0_HOST_RST — USB3.0_HOST. 0: Assert 1: De-assert
    0=Assert; 1=deassert
  [20] USBEHCI0_RST — USBEHCI0 Reset. 0: Assert 1: De-assert
    0=Assert; 1=deassert
  [19] USBOHCI3_RST — USBOHCI3 Reset. 0: Assert 1: De-assert
    0=Assert; 1=deassert
  [16] USBOHCI0_RST — USBOHCI0 Reset. 0: Assert 1: De-assert
    0=Assert; 1=deassert
  [8] USBOTG_GATING — Gating Clock For USBOTG 0: Mask 1: Pass
    0=Mask; 1=Pass
  [7] USBEHCI3_GATING — Gating Clock For USBEHCI3 0: Mask 1: Pass
    0=Mask; 1=Pass
  [5] USB3_0_HOST_GATING — Gating Clock For USB3.0_HOST 0: Mask 1: Pass
    0=Mask; 1=Pass
  [4] USBEHCI0_GATING — Gating Clock For USBEHCI0 0: Mask 1: Pass
    0=Mask; 1=Pass
  [3] USBOHCI3_GATING — Gating Clock For USBOHCI3 0: Mask 1: Pass
    0=Mask; 1=Pass
  [0] USBOHCI0_GATING — Gating Clock For USBOHCI0 0: Mask 1: Pass
    0=Mask; 1=Pass
0xAB0 PCIE_REF_CLK_REG — PCIE REF Clock Register
  [31] SCLK_GATING — Gating Special Clock 0: Clock is OFF 1: Clock is ON SCLK = Clock Source. PLL_PERI0(4X) dividing frequency can get REFCLK_100M.
    0=OFF (Clock is OFF); 1=ON (Clock is ON SCLK = Clock Source. PLL_PERI0(4X) dividing frequency can get REFCLK_100M.)
  [30] PAD_CLK_OUTPUT_GATING — Pad Clock Output Gating 0: Clock Output is OFF 1: Clock Output is ON
    0=OFF (Clock Output is OFF); 1=ON (Clock Output is ON)
0xAB4 PCIE_AUX_CLK_REG — PCIE AUX Clock Register
  [31] SCLK_GATING — Gating Special Clock 0: Clock is OFF 1: Clock is ON SCLK = Clock Source/M. Clock Source is OSC24M.
    0=OFF (Clock is OFF); 1=ON (Clock is ON SCLK = Clock Source/M. Clock Source is OSC24M.)
  [4:0] FACTOR_M — Factor M.(M= FACTOR_M +1) FACTOR_M is from 0 to 31
0xAB4 PCIE_MAXI_CLK_REG
  [31] SCLK_GATING — Gating Special Clock 0: Clock is OFF 1: Clock is ON SCLK = Clock Source/M. Clock Source is PLL_PERI0(1X).
    0=OFF (Clock is OFF); 1=ON (Clock is ON SCLK = Clock Source/M. Clock Source is PLL_PERI0(1X).)
  [3:0] FACTOR_M — Factor M.(M= FACTOR_M +1) FACTOR_M is from 0 to 15
0xABC PCIE_BGR_REG
  [17] PCIE_POWERUP_RST — PCIE Power up Reset. 0: Assert 1: De-assert
    0=Assert; 1=deassert
  [16] PCIE_P_RST — PCIE P Reset. 0: Assert 1: De-assert
    0=Assert; 1=deassert
  [0] PCIE — _GATING. Gating Clock For PCIE 0: Mask 1: Pass
    0=Mask; 1=Pass
0xB00 HDMI_CLK_REG
  [31] SCLK_GATING — Gating Special Clock 0: Clock is OFF 1: Clock is ON SCLK = Clock Source/M.
    values as DE_CLK_REG.SCLK_GATING
  [25:24] CLK_SRC_SEL — Clock Source Select 00: PLL_VIDEO0(1X) 01: PLL_VIDEO1(1X) 10: PLL_VIDEO1(4X) 11: /
    0=PLL_VIDEO0_openingparen_1X_closingparen_ (PLL_VIDEO0(1X)); 1=PLL_VIDEO1_openingparen_1X_closingparen_ (PLL_VIDEO1(1X)); 2=PLL_VIDEO1_openingparen_4X_closingparen_ (PLL_VIDEO1(4X))
  [3:0] FACTOR_M — Factor M.(M= FACTOR_M +1) FACTOR_M is from 0 to 15
0xB04 HDMI_SLOW_CLK_REG — HDMI Slow Clock Register
  fields as AVS_CLK_REG
0xB10 HDMI_CEC_CLK_REG — HDMI CEC Clock Register
  [31] SCLK_GATING — Gating Special Clock 0: Clock is OFF 1: Clock is ON SCLK = OSC24M.
    0=OFF (Clock is OFF); 1=ON (Clock is ON SCLK = OSC24M.)
  [25:24] CLK_SRC_SEL — Clock Source Select 0: CCU_32K 1: PLL_PERI0(2X)/36621 =32.769kHz
0xB1C HDMI_BGR_REG — HDMI Bus Gating Reset Register
  [17] HDMI_SUB_RST — HDMI_SUB Reset. 0: Assert 1: De-assert
    0=Assert; 1=deassert
  [16] HDMI_MAIN_RST — HDMI_MAIN Reset. 0: Assert 1: De-assert
    0=Assert; 1=deassert
  [0] HDMI_GATING — Gating Clock For HDMI 0: Mask 1: Pass
    0=Mask; 1=Pass
0xB5C DISPLAY_IF_TOP_BGR_REG — DISPLAY_IF_TOP Bus Gating Reset Register
  [16] DISPLAY_IF_TOP_RST — DISPLAY_IF_TOP Reset. 0: Assert 1: De-assert
    0=Assert; 1=deassert
  [0] DISPLAY_IF_TOP_GATING — Gating Clock For DISPLAY_IF_TOP 0: Mask 1: Pass
    0=Mask; 1=Pass
0xB60 TCON_LCD_CLK_REG — TCON_LCD Clock Register
  [31] SCLK_GATING — Gating Special Clock 0: Clock is OFF 1: Clock is ON SCLK = Clock Source
    0=OFF (Clock is OFF); 1=ON (Clock is ON SCLK = Clock Source)
  [26:24] CLK_SRC_SEL — Clock Source Select 000: PLL_VIDEO0(1X) 001: PLL_VIDEO0(4X) 010: PLL_VIDEO1(1X) Others:/
    0=PLL_VIDEO0_openingparen_1X_closingparen_ (PLL_VIDEO0(1X)); 1=PLL_VIDEO0_openingparen_4X_closingparen_ (PLL_VIDEO0(4X)); 2=PLL_VIDEO1_openingparen_1X_closingparen_ (PLL_VIDEO1(1X) Others:/)
0xB7C TCON_LCD_BGR_REG — TCON_LCD Bus Gating Reset Register
  [16] TCON_LCD_RST — TCON_LCD Reset. 0: Assert 1: De-assert
    0=Assert; 1=deassert
  [0] TCON_LCD_GATING — Gating Clock For TCON_LCD 0: Mask 1: Pass
    0=Mask; 1=Pass
0xB80 TCON_TV_CLK_REG — TCON_TV Clock Register
  [31] SCLK_GATING — Gating Special Clock 0: Clock is OFF 1: Clock is ON SCLK = Clock Source/M/N.
    values as CE_CLK_REG.SCLK_GATING
  [26:24] CLK_SRC_SEL — Clock Source Select 000: PLL_VIDEO0(1X) 001: PLL_VIDEO0(4X) 010: PLL_VIDEO1(1X) 011: PLL_VIDEO1(4X) Others:/
    0=PLL_VIDEO0_openingparen_1X_closingparen_ (PLL_VIDEO0(1X)); 1=PLL_VIDEO0_openingparen_4X_closingparen_ (PLL_VIDEO0(4X)); 2=PLL_VIDEO1_openingparen_1X_closingparen_ (PLL_VIDEO1(1X)); 3=PLL_VIDEO1_openingparen_4X_closingparen_ (PLL_VIDEO1(4X) Others:/)
  [9:8] FACTOR_N — Factor N 00: 1 01: 2 10: 4 11: 8
    0=_1; 1=_2; 2=_4; 3=_8
  [3:0] FACTOR_M — Factor M.(M= FACTOR_M +1) FACTOR_M is from 0 to 15
0xB9C TCON_TV_BGR_REG — TCON_TV Bus Gating Reset Register
  [16] TCON_TV0_RST — TCON_TV0 Reset. 0: Assert 1: De-assert
    0=Assert; 1=deassert
  [0] TCON_TV0_GATING — Gating Clock For TCON_TV0 0: Mask 1: Pass
    0=Mask; 1=Pass
0xC00 CSI_MISC_CLK_REG — CSI MISC Clock Register
  [0] CSI_CCI_CLK_GATING — Gating CCI Special Clock,Clock source is OSC24M 0: Clock is OFF 1: Clock is ON
    0=OFF (Clock is OFF); 1=ON (Clock is ON)
0xC04 CSI_TOP_CLK_REG — CSI TOP Clock Register
  [31] SCLK_GATING — Gating Special Clock 0: Clock is OFF 1: Clock is ON SCLK = Clock Source/M.
    values as DE_CLK_REG.SCLK_GATING
  [26:24] CLK_SRC_SEL — Clock Source Select 000:PLL_VIDEO0(1X) 001:/ 010:PLL_VE 011:PLL_PERI0(1X) Others:/
  [3:0] FACTOR_M — Factor M.(M= FACTOR_M +1) FACTOR_M is from 0 to 15
0xC08 CSI0_MST_CLK_REG
  [31] MCLK0_GATING — Gating CSI Master Clock0,this clock output to external device. 0: Clock is OFF 1: Clock is ON MCLK0 = Clock Source/M
    0=OFF (Clock is OFF); 1=ON (Clock is ON MCLK0 = Clock Source/M)
  [26:24] CLK_SRC_SEL — Clock Source Select 000: OSC24M 001: PLL_VIDEO0(1X) 010: PLL_PERI0(1X) 011: PLL_PERI1(1X) Others:/
    0=OSC24M; 1=PLL_VIDEO0_openingparen_1X_closingparen_ (PLL_VIDEO0(1X)); 2=PLL_PERI0_openingparen_1X_closingparen_ (PLL_PERI0(1X)); 3=PLL_PERI1_openingparen_1X_closingparen_ (PLL_PERI1(1X) Others:/)
  [4:0] FACTOR_M — Factor M.(M= FACTOR_M +1) FACTOR_M is from 0 to 31
0xC2C CSI_BGR_REG — CSI Bus Gating Reset Register
  [16] CSI_RST — CSI Reset. 0: Assert 1: De-assert
    0=Assert; 1=deassert
  [0] CSI_GATING — Gating Clock For CSI 0: Mask 1: Pass
    0=Mask; 1=Pass
0xC40 HDMI_HDCP_CLK_REG — HDMI HDCP Clock Register
  [31] SCLK_GATING — Gating Special Clock 0: Clock is OFF 1: Clock is ON SCLK = Clock Source/M.
    values as DE_CLK_REG.SCLK_GATING
  [25:24] CLK_SRC_SEL — Clock Source Select 00: PLL_PERI0(1X) 01: PLL_PERI1(1X) Others:/
    0=PLL_PERI0_openingparen_1X_closingparen_ (PLL_PERI0(1X)); 1=PLL_PERI1_openingparen_1X_closingparen_ (PLL_PERI1(1X) Others:/)
  [3:0] FACTOR_M — Factor M.(M= FACTOR_M +1) FACTOR_M is from 0 to 15
0xC4C HDMI_HDCP_BGR_REG
  [16] HDMI_HDCP_RST — HDMI_HDCP Reset. 0: Assert 1: De-assert
    0=Assert; 1=deassert
  [0] HDMI_HDCP_GATING — Gating Clock For HDMI_HDCP 0: Mask 1: Pass
    0=Mask; 1=Pass
0xF00 CCU_SEC_SWITCH_REG — CCU Security Switch Register
  [all] fields
    0=Secure; 1=non_secure
  [2] MBUS_SEC — MBUS clock register security. 0: Secure 1: Non-secure
  [1] BUS_SEC — Bus relevant registers' security. 0: Secure 1: Non-secure
  [0] PLL_SEC — PLL relevant registers' security. 0: Secure 1: Non-secure
0xF04 PLL_LOCK_DBG_CTRL_REG — PLL Lock Debug Control Register
  [31] DBG_EN — Debug Enable 0: Disable 1: Enable
    0=Disable; 1=Enable
  [24:20] DBG_SEL — Debug Select 00000: PLL_CPUX 00001: / 00010: PLL_DDR0 00011:/ 00100: PLL_PERI0(2X) 00101: PLL_PERI1(2X) 00110:PLL_GPU 00111:/ 01000: PLL_VIDEO0(4X) 01001: PLL_VIDEO1(4X) 01010: / 01011: PLL_VE 01100: PLL_DE 01101: / 01110: PLL_HSIC 01111: PLL_AUDIO Others: /
    0=PLL_CPUX; 2=PLL_DDR0 (PLL_DDR0 00011:/); 4=PLL_PERI0_openingparen_2X_closingparen_ (PLL_PERI0(2X)); 5=PLL_PERI1_openingparen_2X_closingparen_ (PLL_PERI1(2X) 00110:PLL_GPU 00111:/); 8=PLL_VIDEO0_openingparen_4X_closingparen_ (PLL_VIDEO0(4X)); 9=PLL_VIDEO1_openingparen_4X_closingparen_ (PLL_VIDEO1(4X)); 11=PLL_VE; 12=PLL_DE; 14=PLL_HSIC; 15=PLL_AUDIO (PLL_AUDIO Others: /)
  [18:17] UNLOCK_LEVEL — Unlock Level 00: 21-29 Clock Cycles 01: 22-28 Clock Cycles 1X: 20-30 Clock Cycles
    0=_21_minus_29 (21-29 Clock Cycles); 1=_22_minus_28 (22-28 Clock Cycles); 2=_20_minus_30 (20-30 Clock Cycles)
  [16] LOCK_LEVEL — Lock Level 0: 24-26 Clock Cycles 1: 23-27 Clock Cycles
    0=_24_minus_26 (24-26 Clock Cycles); 1=_23_minus_27 (23-27 Clock Cycles)
